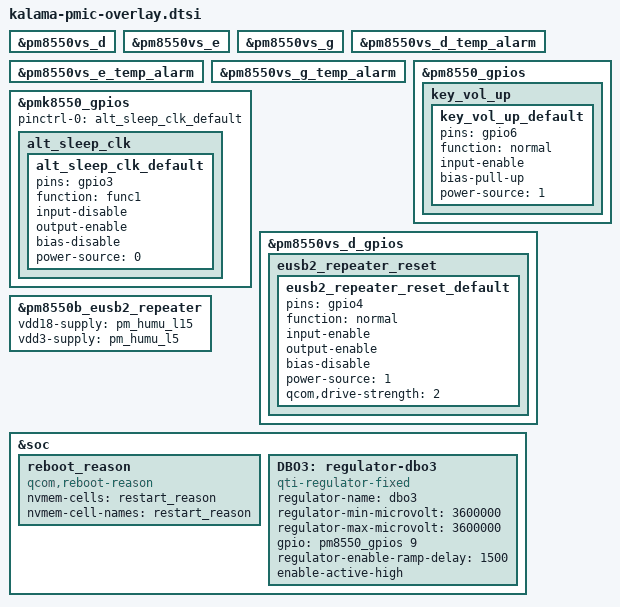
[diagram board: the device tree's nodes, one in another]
#include <dt-bindings/gpio/gpio.h>
#include <dt-bindings/pinctrl/qcom,pmic-gpio.h>

#include "pm8550.dtsi"
#include "pm8550b.dtsi"
#include "pm8550ve.dtsi"
#include "pm8550vs.dtsi"
#include "pmk8550.dtsi"
#include "pmr735d.dtsi"

&pm8550vs_d {
	status = "ok";
};

&pm8550vs_e {
	status = "ok";
};

&pm8550vs_g {
	status = "ok";
};

&pm8550vs_d_temp_alarm {
	status = "ok";
};

&pm8550vs_e_temp_alarm {
	status = "ok";
};

&pm8550vs_g_temp_alarm {
	status = "ok";
};

&pm8550_gpios {
	key_vol_up {
		key_vol_up_default: key_vol_up_default {
			pins = "gpio6";
			function = "normal";
			input-enable;
			bias-pull-up;
			power-source = <1>;
		};
	};
};

&pmk8550_gpios {
	pinctrl-0 = <&alt_sleep_clk_default>;
	pinctrl-names = "default";

	alt_sleep_clk {
		alt_sleep_clk_default: alt_sleep_clk_default {
			pins = "gpio3";
			function = "func1";
			input-disable;
			output-enable;
			bias-disable;
			power-source = <0>;
		};
	};
};

&pm8550vs_d_gpios {
	eusb2_repeater_reset {
		eusb2_repeater_reset_default: eusb2_repeater_reset_default {
			pins = "gpio4";
			function = "normal";
			input-enable;
			output-enable;
			bias-disable;
			power-source = <1>; /* 1.8V */
			qcom,drive-strength = <2>;
		};
	};
};

&pm8550b_eusb2_repeater {
	vdd18-supply = <&pm_humu_l15>;
	vdd3-supply = <&pm_humu_l5>;
};

&soc {
	reboot_reason {
		compatible = "qcom,reboot-reason";
		nvmem-cells = <&restart_reason>;
		nvmem-cell-names = "restart_reason";
	};

	DBO3: regulator-dbo3 {
		compatible = "qti-regulator-fixed";
		regulator-name = "dbo3";
		regulator-min-microvolt = <3600000>;
		regulator-max-microvolt = <3600000>;
		gpio = <&pm8550_gpios 9 GPIO_ACTIVE_HIGH>;
		regulator-enable-ramp-delay = <1500>;
		enable-active-high;
	};
};
